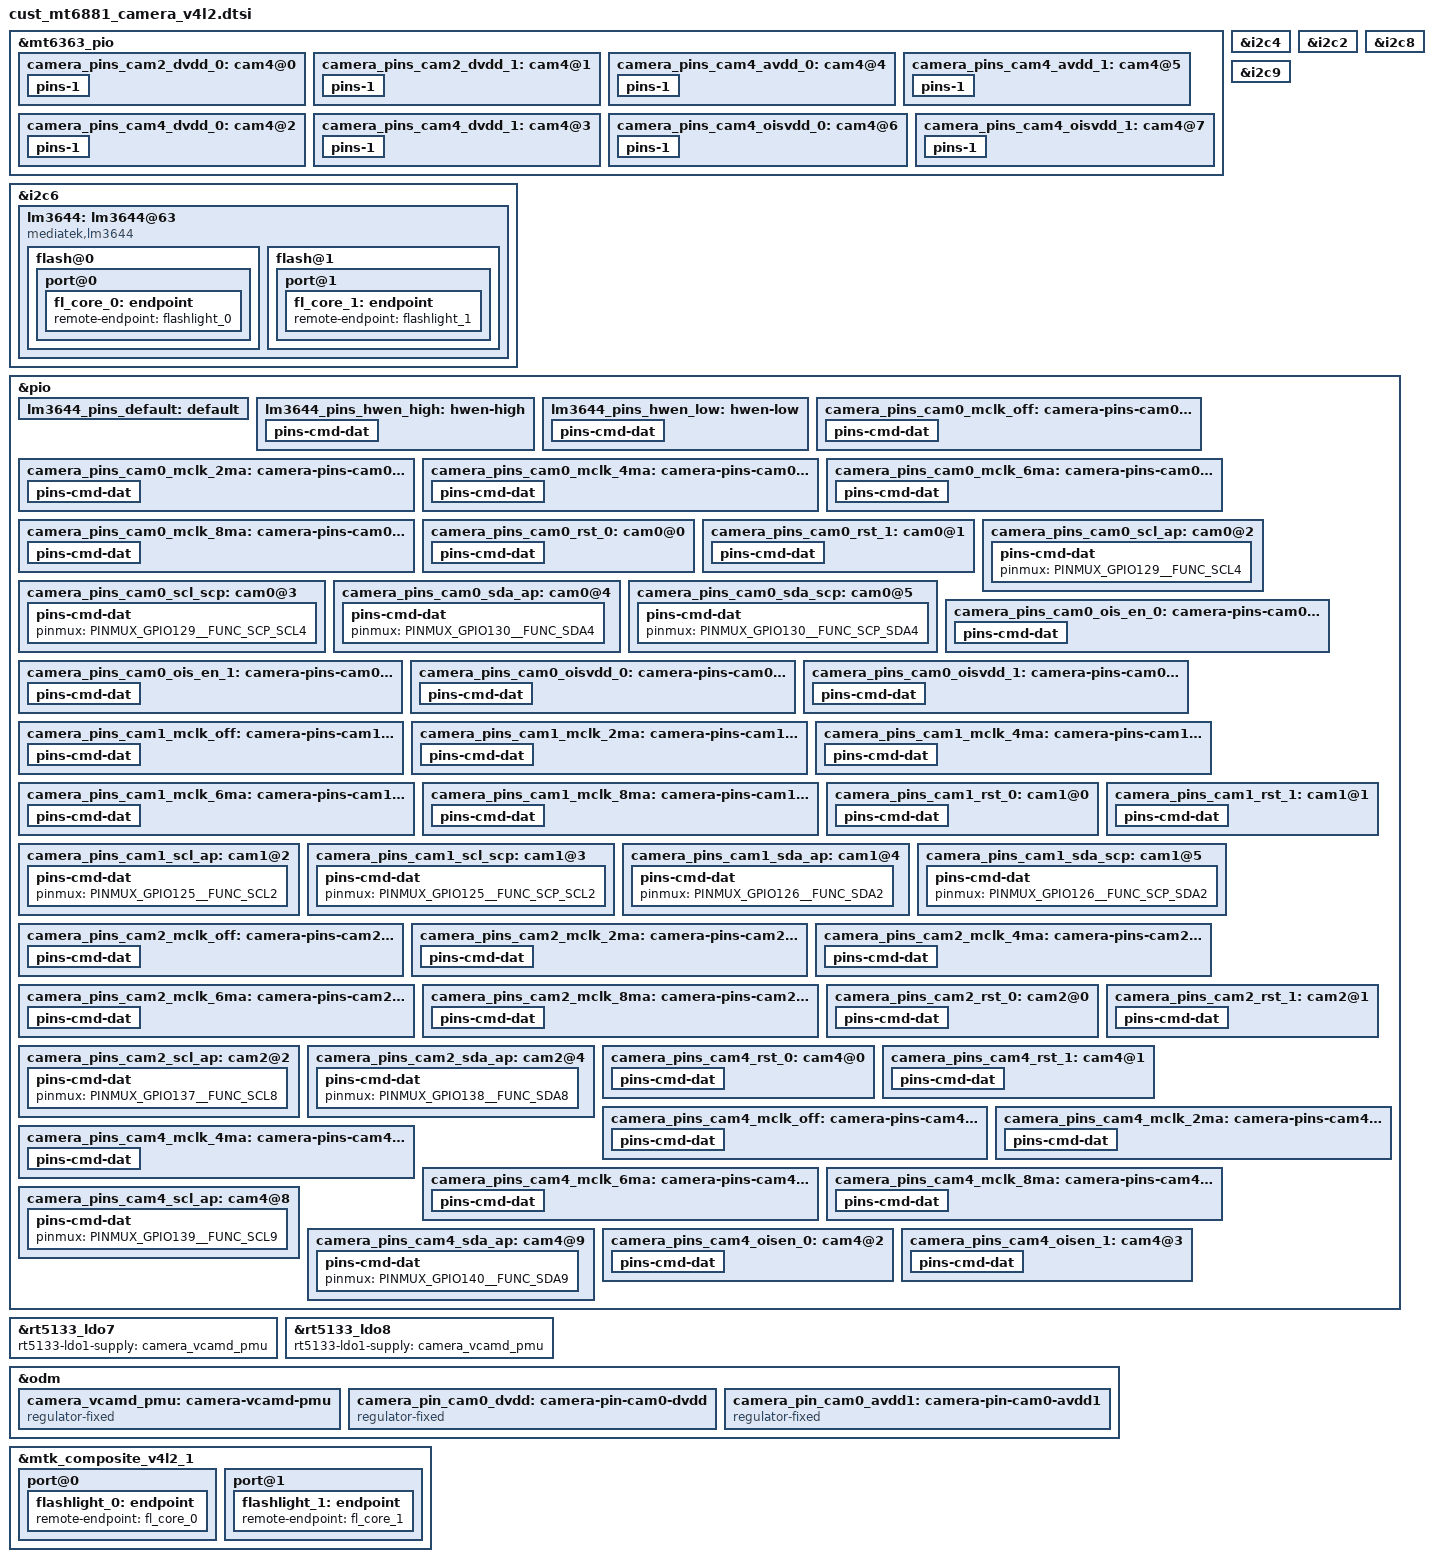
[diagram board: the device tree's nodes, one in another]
// SPDX-License-Identifier: GPL-2.0
/* Copyright (c) 2025 MediaTek Inc. */
#include <dt-bindings/clock/mt6881-clk.h>
#include <dt-bindings/pinctrl/mt6881-pinfunc.h>
#include <dt-bindings/pinctrl/mt6363-pinfunc.h>

#if 0
&seninf_top {
		seninf_csi_port_0: seninf-csi-port-0 {
			compatible = "mediatek,seninf";
			csi-port = "0";

			// nvmem-cells = <&csi_efuse0>;
			// nvmem-cell-names = "rg_csi";

			port {
				seninf_csi_port_0_in: endpoint {
					remote-endpoint = <&sensor1_out>;
				};
			};
		};

		seninf_csi_port_1: seninf-csi-port-1 {
			compatible = "mediatek,seninf";
			csi-port = "1";

			// nvmem-cells = <&csi_efuse1>;
			// nvmem-cell-names = "rg_csi";

			/* HP9 EINT */
			interrupts-extended = <&pio 23 IRQ_TYPE_EDGE_FALLING>;
			gpio-num = <23>;
			eint-no = <3>; /* Max to 3, options:{1, 2, 3} */

			port {
				seninf_csi_port_1_in: endpoint {
					remote-endpoint = <&sensor4_out>;
				};
			};
		};

		seninf_csi_port_2: seninf-csi-port-2 {
			compatible = "mediatek,seninf";
			csi-port = "2";


			// nvmem-cells = <&csi_efuse2>;
			// nvmem-cell-names = "rg_csi";


			/* JN1 EINT */
			interrupts-extended = <&pio 22 IRQ_TYPE_EDGE_FALLING>;
			gpio-num = <22>;
			eint-no = <2>; /* Max to 3, options:{1, 2, 3} */

			port {
				seninf_csi_port_2_in: endpoint {
					remote-endpoint = <&sensor2_out>;
				};
			};
		};
		seninf_csi_port_3: seninf-csi-port-3 {
			compatible = "mediatek,seninf";
			csi-port = "3";

			// nvmem-cells = <&csi_efuse3>;
			// nvmem-cell-names = "rg_csi";


			/* KOKU EINT */
			interrupts-extended = <&pio 96 IRQ_TYPE_EDGE_FALLING>;
			gpio-num = <96>;
			eint-no = <1>; /* Max to 3, options:{1, 2, 3} */

			port {
				seninf_csi_port_3_in: endpoint@1 {
					remote-endpoint = <&sensor0_out>;
				};
			};
		};
};
#endif

&mt6363_pio {
	camera_pins_cam2_dvdd_0: cam4@0 {
		pins-1 {
			pinmux = <PINMUX_MT6363_GPIO4__FUNC_GPIO4>;
			drive-strengh = <15>;
			output-low;
		};
	};

	camera_pins_cam2_dvdd_1: cam4@1 {
		pins-1 {
			pinmux = <PINMUX_MT6363_GPIO4__FUNC_GPIO4>;
			drive-strengh = <15>;
			output-high;
		};
	};

	camera_pins_cam4_avdd_0: cam4@4 {
		pins-1 {
			pinmux = <PINMUX_MT6363_GPIO7__FUNC_GPIO7>;
			drive-strengh = <15>;
			output-low;
		};
	};
	camera_pins_cam4_avdd_1: cam4@5 {
		pins-1 {
			pinmux = <PINMUX_MT6363_GPIO7__FUNC_GPIO7>;
			drive-strengh = <15>;
			output-high;
		};
	};

	camera_pins_cam4_dvdd_0: cam4@2 {
		pins-1 {
			pinmux = <PINMUX_MT6363_GPIO5__FUNC_GPIO5>;
			drive-strengh = <15>;
			output-low;
		};
	};

	camera_pins_cam4_dvdd_1: cam4@3 {
		pins-1 {
			pinmux = <PINMUX_MT6363_GPIO5__FUNC_GPIO5>;
			drive-strengh = <15>;
			output-high;
		};
	};

	camera_pins_cam4_oisvdd_0: cam4@6 {
		pins-1 {
			pinmux = <PINMUX_MT6363_GPIO6__FUNC_GPIO6>;
			drive-strengh = <15>;
			output-low;
		};
	};
	camera_pins_cam4_oisvdd_1: cam4@7 {
		pins-1 {
			pinmux = <PINMUX_MT6363_GPIO6__FUNC_GPIO6>;
			drive-strengh = <15>;
			output-high;
		};
	};
};

&i2c6 {
	lm3644:lm3644@63 {
		compatible = "mediatek,lm3644";
		reg = <0x63>;
		#cooling-cells = <2>;
		pinctrl-names = "default", "hwen-high", "hwen-low";
		pinctrl-0 = <&lm3644_pins_default>;
		pinctrl-1 = <&lm3644_pins_hwen_high>;
		pinctrl-2 = <&lm3644_pins_hwen_low>;
		status = "okay";
		flash@0{
			reg = <0>;
			type = <0>;
			ct = <0>;
			part = <0>;
			port@0 {
				fl_core_0: endpoint {
					remote-endpoint = <&flashlight_0>;
				};
			};
		};
		flash@1{
			reg = <1>;
			type = <0>;
			ct = <1>;
			part = <0>;
			port@1 {
				fl_core_1: endpoint {
					remote-endpoint = <&flashlight_1>;
				};
			};
		};
	};
};

&i2c4 {
#if 0
	status = "okay";
	clock-frequency = <1000000>;

	sensor0: sensor0@36 {
		compatible = "mediatek,imgsensor";
		sensor-names = "ov48b_mipi_raw",
					"imx06c_mipi_raw";
		reg = <0x36 0 0>;
		maximum-pmic-delay = <4000>;

		#thermal-sensor-cells = <0>;

		pinctrl-names = "mclk_off",
				"mclk_2mA",
				"mclk_4mA",
				"mclk_6mA",
				"mclk_8mA",
				"rst_low",
				"rst_high",
				"scl_ap",
				"scl_scp",
				"sda_ap",
				"sda_scp",
				"oisvdd_off",
				"oisvdd_on",
				"oisen_off",
				"oisen_on";
		pinctrl-0 = <&camera_pins_cam0_mclk_off>;
		pinctrl-1 = <&camera_pins_cam0_mclk_2ma>;
		pinctrl-2 = <&camera_pins_cam0_mclk_4ma>;
		pinctrl-3 = <&camera_pins_cam0_mclk_6ma>;
		pinctrl-4 = <&camera_pins_cam0_mclk_8ma>;
		pinctrl-5 = <&camera_pins_cam0_rst_0>;
		pinctrl-6 = <&camera_pins_cam0_rst_1>;
		pinctrl-7 = <&camera_pins_cam0_scl_ap>;
		pinctrl-8 = <&camera_pins_cam0_scl_scp>;
		pinctrl-9 = <&camera_pins_cam0_sda_ap>;
		pinctrl-10 = <&camera_pins_cam0_sda_scp>;
		pinctrl-11 = <&camera_pins_cam0_oisvdd_0>;
		pinctrl-12 = <&camera_pins_cam0_oisvdd_1>;
		pinctrl-13 = <&camera_pins_cam0_ois_en_0>;
		pinctrl-14 = <&camera_pins_cam0_ois_en_1>;

		avdd-supply =  <&rt5133_ldo5>;  // 2.8V
		avdd1-supply =  <&camera_pin_cam0_avdd1>;  // 1.8V
		dvdd-supply = <&rt5133_ldo7>;  // 1.1v for ov48b
		dvdd1-supply = <&camera_pin_cam0_dvdd>;  // 0.81v for tri cam
		afvdd1-supply = <&rt5133_gpio1>;
		dovdd-supply = <&camera_vcamd_pmu>;  // iovdd 1.8v share
		base-supply = <&rt5133_base>;

		clocks = <&cksys_reg_clk CLK_CKSYS_REG_UNIVPLL_192M_D32>,
			<&cksys_reg_clk CLK_CKSYS_REG_UNIVPLL_192M_D16>,
			<&cksys_reg_clk CLK_CKSYS_REG_F26M_CK_D2>,
			<&cksys_reg_clk CLK_CKSYS_REG_UNIVPLL_192M_D10>,
			<&cksys_reg_clk CLK_CKSYS_REG_UNIVPLL_192M_D8>,
			<&cksys_reg_clk CLK_CKSYS_REG_TCK_26M_MX9>,
			<&cksys_reg_clk CLK_CKSYS_REG_OSC_D10>,
			<&cksys_reg_clk CLK_CKSYS_REG_UNIVPLL_D6_D8>,
			<&cksys_reg_clk CLK_CKSYS_REG_CAMTG1_SEL>;

		clock-names = "6", "12", "13", "19.2", "24", "26", "26_ulposc", "52", "mclk";


		status = "okay";
		port {
			sensor0_out: endpoint {
				remote-endpoint = <&seninf_csi_port_3_in>;
			};
		};
	};

	mtk_camera_eeprom:camera-eeprom0@50 {
		compatible = "mediatek,camera_eeprom";
		reg = <0x50 0 0>;
		names = "imx06c_cust_eeprom",
			"ov48b_mtk_eeprom";
		status = "okay";
	};
#endif
};

&i2c2 {
#if 0
	status = "okay";
	clock-frequency = <1000000>;

	sensor1: sensor1@10 {
		compatible = "mediatek,imgsensor";
		sensor-names = "s5k3p9sp_mipi_raw";
		reg = <0x10>;
		maximum-pmic-delay = <4000>;

		#thermal-sensor-cells = <0>;

		pinctrl-names = "mclk_off",
				"mclk_2mA",
				"mclk_4mA",
				"mclk_6mA",
				"mclk_8mA",
				"rst_low",
				"rst_high",
				"scl_ap",
				"scl_scp",
				"sda_ap",
				"sda_scp";
		pinctrl-0 = <&camera_pins_cam1_mclk_off>;
		pinctrl-1 = <&camera_pins_cam1_mclk_2ma>;
		pinctrl-2 = <&camera_pins_cam1_mclk_4ma>;
		pinctrl-3 = <&camera_pins_cam1_mclk_6ma>;
		pinctrl-4 = <&camera_pins_cam1_mclk_8ma>;
		pinctrl-5 = <&camera_pins_cam1_rst_0>;
		pinctrl-6 = <&camera_pins_cam1_rst_1>;
		pinctrl-7 = <&camera_pins_cam1_scl_ap>;
		pinctrl-8 = <&camera_pins_cam1_scl_scp>;
		pinctrl-9 = <&camera_pins_cam1_sda_ap>;
		pinctrl-10 = <&camera_pins_cam1_sda_scp>;

		avdd-supply = <&rt5133_ldo3>;
		dvdd-supply = <&rt5133_gpio3>;
		dovdd-supply = <&camera_vcamd_pmu>;
		base-supply = <&rt5133_base>;

		clocks = <&cksys_reg_clk CLK_CKSYS_REG_UNIVPLL_192M_D32>,
			<&cksys_reg_clk CLK_CKSYS_REG_UNIVPLL_192M_D16>,
			<&cksys_reg_clk CLK_CKSYS_REG_F26M_CK_D2>,
			<&cksys_reg_clk CLK_CKSYS_REG_UNIVPLL_192M_D10>,
			<&cksys_reg_clk CLK_CKSYS_REG_UNIVPLL_192M_D8>,
			<&cksys_reg_clk CLK_CKSYS_REG_TCK_26M_MX9>,
			<&cksys_reg_clk CLK_CKSYS_REG_OSC_D10>,
			<&cksys_reg_clk CLK_CKSYS_REG_UNIVPLL_D6_D8>,
			<&cksys_reg_clk CLK_CKSYS_REG_CAMTG0_SEL>;
		clock-names = "6", "12", "13", "19.2", "24", "26", "26_ulposc", "52", "mclk";

		status = "okay";
		port {
			sensor1_out: endpoint {
				remote-endpoint = <&seninf_csi_port_0_in>;
			};
		};
	};

	mtk_camera_eeprom1:camera-eeprom1@50 {
		compatible = "mediatek,camera_eeprom";
		reg = <0x50 0 0>;
		names = "s5k3p9sp_mtk_eeprom";
		status = "okay";
	};
#endif
};

&i2c8 {
#if 0
	status = "okay";
	clock-frequency = <1000000>;

	sensor2: sensor2@10 {
		compatible = "mediatek,imgsensor";
		sensor-names = "s5kjn1_mipi_raw";
		reg = <0x10>;
		maximum-pmic-delay = <4000>;

		cust-aov-csi-clk = <312>;

		#thermal-sensor-cells = <0>;

		pinctrl-names = "mclk_off",
				"mclk_2mA",
				"mclk_4mA",
				"mclk_6mA",
				"mclk_8mA",
				"rst_low",
				"rst_high",
				"dvdd_off",
				"dvdd_on",
				"scl_ap",
				"sda_ap";

		pinctrl-0 = <&camera_pins_cam2_mclk_off>;
		pinctrl-1 = <&camera_pins_cam2_mclk_2ma>;
		pinctrl-2 = <&camera_pins_cam2_mclk_4ma>;
		pinctrl-3 = <&camera_pins_cam2_mclk_6ma>;
		pinctrl-4 = <&camera_pins_cam2_mclk_8ma>;
		pinctrl-5 = <&camera_pins_cam2_rst_0>;
		pinctrl-6 = <&camera_pins_cam2_rst_1>;
		pinctrl-7 = <&camera_pins_cam2_dvdd_0>;
		pinctrl-8 = <&camera_pins_cam2_dvdd_1>;
		pinctrl-9 = <&camera_pins_cam2_scl_ap>;
		pinctrl-10 = <&camera_pins_cam2_sda_ap>;

		avdd-supply = <&rt5133_ldo3>;
		afvdd-supply = <&rt5133_ldo2>;
		dovdd-supply = <&camera_vcamd_pmu>;
		base-supply = <&rt5133_base>;

		clocks = <&cksys_reg_clk CLK_CKSYS_REG_UNIVPLL_192M_D32>,
			<&cksys_reg_clk CLK_CKSYS_REG_UNIVPLL_192M_D16>,
			<&cksys_reg_clk CLK_CKSYS_REG_F26M_CK_D2>,
			<&cksys_reg_clk CLK_CKSYS_REG_UNIVPLL_192M_D10>,
			<&cksys_reg_clk CLK_CKSYS_REG_UNIVPLL_192M_D8>,
			<&cksys_reg_clk CLK_CKSYS_REG_TCK_26M_MX9>,
			<&cksys_reg_clk CLK_CKSYS_REG_OSC_D10>,
			<&cksys_reg_clk CLK_CKSYS_REG_UNIVPLL_D6_D8>,
			<&cksys_reg_clk CLK_CKSYS_REG_CAMTG4_SEL>;
		clock-names = "6", "12", "13", "19.2", "24", "26", "26_ulposc", "52", "mclk";

		status = "okay";
		port {
			sensor2_out: endpoint {
				remote-endpoint = <&seninf_csi_port_2_in>;
			};
		};
	};

	mtk_camera_eeprom2:camera-eeprom2@54 {
		compatible = "mediatek,camera_eeprom";
		reg = <0x54>;
		names = "s5kjn1_cust_eeprom";
		status = "okay";
	};
#endif
};

&i2c9 {
#if 0
	compatible = "mediatek,mt6991-i3c";
	#address-cells = <3>;
	#size-cells = <0>;
	i3c-scl-hz = <12000000>;
	status = "okay";

	sensor4: sensor4@10 {
		compatible = "mediatek,imgsensor";
		sensor-names = "s5khp9sp_mipi_raw";
		reg = <0x26 0x0216 0x1b730000>;
		assigned-address = <0x26>;
		pre-cfg-addr = <0x10>;
		maximum-pmic-delay = <4000>;

		#thermal-sensor-cells = <0>;

		pinctrl-names = "mclk_off",
				"mclk_2mA",
				"mclk_4mA",
				"mclk_6mA",
				"mclk_8mA",
				"rst_low",
				"rst_high",
				"scl_ap",
				"sda_ap",
				"avdd_off",
				"avdd_on",
				"dvdd_off",
				"dvdd_on",
				"oisvdd_off",
				"oisvdd_on",
				"oisen_off",
				"oisen_on";
		pinctrl-0 = <&camera_pins_cam4_mclk_off>;
		pinctrl-1 = <&camera_pins_cam4_mclk_2ma>;
		pinctrl-2 = <&camera_pins_cam4_mclk_4ma>;
		pinctrl-3 = <&camera_pins_cam4_mclk_6ma>;
		pinctrl-4 = <&camera_pins_cam4_mclk_8ma>;
		pinctrl-5 = <&camera_pins_cam4_rst_0>;
		pinctrl-6 = <&camera_pins_cam4_rst_1>;
		pinctrl-7 = <&camera_pins_cam4_scl_ap>;
		pinctrl-8 = <&camera_pins_cam4_sda_ap>;
		pinctrl-9 = <&camera_pins_cam4_avdd_0>;
		pinctrl-10 = <&camera_pins_cam4_avdd_1>;
		pinctrl-11 = <&camera_pins_cam4_dvdd_0>;
		pinctrl-12 = <&camera_pins_cam4_dvdd_1>;
		pinctrl-13 = <&camera_pins_cam4_oisvdd_0>;
		pinctrl-14 = <&camera_pins_cam4_oisvdd_1>;
		pinctrl-15 = <&camera_pins_cam4_oisen_0>;
		pinctrl-16 = <&camera_pins_cam4_oisen_1>;

		afvdd-supply = <&rt5133_ldo2>;
		dovdd-supply = <&camera_vcamd_pmu>;
		base-supply = <&rt5133_base>;

		clocks = <&cksys_reg_clk CLK_CKSYS_REG_UNIVPLL_192M_D32>,
			<&cksys_reg_clk CLK_CKSYS_REG_UNIVPLL_192M_D16>,
			<&cksys_reg_clk CLK_CKSYS_REG_F26M_CK_D2>,
			<&cksys_reg_clk CLK_CKSYS_REG_UNIVPLL_192M_D10>,
			<&cksys_reg_clk CLK_CKSYS_REG_UNIVPLL_192M_D8>,
			<&cksys_reg_clk CLK_CKSYS_REG_TCK_26M_MX9>,
			<&cksys_reg_clk CLK_CKSYS_REG_OSC_D10>,
			<&cksys_reg_clk CLK_CKSYS_REG_UNIVPLL_D6_D8>,
			<&cksys_reg_clk CLK_CKSYS_REG_CAMTG2_SEL>;

		clock-names = "6", "12", "13", "19.2", "24", "26", "26_ulposc", "52", "mclk";


		status = "okay";
		port {
			sensor4_out: endpoint {
				remote-endpoint = <&seninf_csi_port_1_in>;
			};
		};
	};

	mtk_camera_eeprom4:camera-eeprom4@55 {
		compatible = "mediatek,camera_eeprom";
		reg = <0x55 0 0>;
		names = "s5khp9sp_cust_eeprom";
		status = "okay";
	};
#endif
};

&pio {
	lm3644_pins_default: default {
	};

	lm3644_pins_hwen_high: hwen-high {
		pins-cmd-dat {
			pinmux = <PINMUX_GPIO99__FUNC_GPIO99>;
			slew-rate = <1>;
			output-high;
		};
	};

	lm3644_pins_hwen_low: hwen-low {
		pins-cmd-dat {
			pinmux = <PINMUX_GPIO99__FUNC_GPIO99>;
			slew-rate = <1>;
			output-low;
		};
	};

	camera_pins_cam0_mclk_off: camera-pins-cam0-mclk-off {
		pins-cmd-dat {
			pinmux = <PINMUX_GPIO67__FUNC_GPIO67>;
			drive-strength = <1>;
		};
	};
	camera_pins_cam0_mclk_2ma: camera-pins-cam0-mclk-2ma {
		pins-cmd-dat {
			pinmux = <PINMUX_GPIO67__FUNC_CMMCLK1>;
			drive-strength = <0>;
		};
	};
	camera_pins_cam0_mclk_4ma: camera-pins-cam0-mclk-4ma {
		pins-cmd-dat {
			pinmux = <PINMUX_GPIO67__FUNC_CMMCLK1>;
			drive-strength = <1>;
		};
	};
	camera_pins_cam0_mclk_6ma: camera-pins-cam0-mclk-6ma {
		pins-cmd-dat {
			pinmux = <PINMUX_GPIO67__FUNC_CMMCLK1>;
			drive-strength = <2>;
		};
	};
	camera_pins_cam0_mclk_8ma: camera-pins-cam0-mclk-8ma {
		pins-cmd-dat {
			pinmux = <PINMUX_GPIO67__FUNC_CMMCLK1>;
			drive-strength = <3>;
		};
	};

	camera_pins_cam0_rst_0: cam0@0 {
		pins-cmd-dat {
			pinmux = <PINMUX_GPIO63__FUNC_GPIO63>;
			slew-rate = <1>;
			output-low;
		};
	};
	camera_pins_cam0_rst_1: cam0@1 {
		pins-cmd-dat {
			pinmux = <PINMUX_GPIO63__FUNC_GPIO63>;
			slew-rate = <1>;
			output-high;
		};
	};

	camera_pins_cam0_scl_ap: cam0@2 {
		pins-cmd-dat {
			pinmux = <PINMUX_GPIO129__FUNC_SCL4>;
		};
	};
	camera_pins_cam0_scl_scp: cam0@3 {
		pins-cmd-dat {
			pinmux = <PINMUX_GPIO129__FUNC_SCP_SCL4>;
		};
	};
	camera_pins_cam0_sda_ap: cam0@4 {
		pins-cmd-dat {
			pinmux = <PINMUX_GPIO130__FUNC_SDA4>;
		};
	};
	camera_pins_cam0_sda_scp: cam0@5 {
		pins-cmd-dat {
			pinmux = <PINMUX_GPIO130__FUNC_SCP_SDA4>;
		};
	};
	camera_pins_cam0_ois_en_0: camera-pins-cam0-ois-en-0 {
		pins-cmd-dat {
			pinmux = <PINMUX_GPIO26__FUNC_GPIO26>;
			slew-rate = <1>;
			output-low;
		};
	};
	camera_pins_cam0_ois_en_1: camera-pins-cam0-ois-en-1 {
		pins-cmd-dat {
			pinmux = <PINMUX_GPIO26__FUNC_GPIO26>;
			slew-rate = <1>;
			output-high;
		};
	};
	camera_pins_cam0_oisvdd_0: camera-pins-cam0-oisvdd-0 {
		pins-cmd-dat {
			pinmux = <PINMUX_GPIO142__FUNC_GPIO142>;
			slew-rate = <1>;
			output-low;
		};
	};
	camera_pins_cam0_oisvdd_1: camera-pins-cam0-oisvdd-1 {
		pins-cmd-dat {
			pinmux = <PINMUX_GPIO142__FUNC_GPIO142>;
			slew-rate = <1>;
			output-high;
		};
	};

	camera_pins_cam1_mclk_off: camera-pins-cam1-mclk-off {
		pins-cmd-dat {
			pinmux = <PINMUX_GPIO66__FUNC_GPIO66>;
			drive-strength = <1>;
		};
	};
	camera_pins_cam1_mclk_2ma: camera-pins-cam1-mclk-2ma {
		pins-cmd-dat {
			pinmux = <PINMUX_GPIO66__FUNC_CMMCLK0>;
			drive-strength = <0>;
		};
	};
	camera_pins_cam1_mclk_4ma: camera-pins-cam1-mclk-4ma {
		pins-cmd-dat {
			pinmux = <PINMUX_GPIO66__FUNC_CMMCLK0>;
			drive-strength = <1>;
		};
	};
	camera_pins_cam1_mclk_6ma: camera-pins-cam1-mclk-6ma {
		pins-cmd-dat {
			pinmux = <PINMUX_GPIO66__FUNC_CMMCLK0>;
			drive-strength = <2>;
		};
	};
	camera_pins_cam1_mclk_8ma: camera-pins-cam1-mclk-8ma {
		pins-cmd-dat {
			pinmux = <PINMUX_GPIO66__FUNC_CMMCLK0>;
			drive-strength = <3>;
		};
	};
	camera_pins_cam1_rst_0: cam1@0 {
		pins-cmd-dat {
			pinmux = <PINMUX_GPIO62__FUNC_GPIO62>;
			slew-rate = <1>;
			output-low;
		};
	};
	camera_pins_cam1_rst_1: cam1@1 {
		pins-cmd-dat {
			pinmux = <PINMUX_GPIO62__FUNC_GPIO62>;
			slew-rate = <1>;
			output-high;
		};
	};
	camera_pins_cam1_scl_ap: cam1@2 {
		pins-cmd-dat {
			pinmux = <PINMUX_GPIO125__FUNC_SCL2>;
		};
	};
	camera_pins_cam1_scl_scp: cam1@3 {
		pins-cmd-dat {
			pinmux = <PINMUX_GPIO125__FUNC_SCP_SCL2>;
		};
	};
	camera_pins_cam1_sda_ap: cam1@4 {
		pins-cmd-dat {
			pinmux = <PINMUX_GPIO126__FUNC_SDA2>;
		};
	};
	camera_pins_cam1_sda_scp: cam1@5 {
		pins-cmd-dat {
			pinmux = <PINMUX_GPIO126__FUNC_SCP_SDA2>;
		};
	};

	camera_pins_cam2_mclk_off: camera-pins-cam2-mclk-off {
		pins-cmd-dat {
			pinmux = <PINMUX_GPIO68__FUNC_GPIO68>;
			drive-strength = <1>;
		};
	};
	camera_pins_cam2_mclk_2ma: camera-pins-cam2-mclk-2ma {
		pins-cmd-dat {
			pinmux = <PINMUX_GPIO68__FUNC_CMMCLK2>;
			drive-strength = <0>;
		};
	};
	camera_pins_cam2_mclk_4ma: camera-pins-cam2-mclk-4ma {
		pins-cmd-dat {
			pinmux = <PINMUX_GPIO68__FUNC_CMMCLK2>;
			drive-strength = <1>;
		};
	};
	camera_pins_cam2_mclk_6ma: camera-pins-cam2-mclk-6ma {
		pins-cmd-dat {
			pinmux = <PINMUX_GPIO68__FUNC_CMMCLK2>;
			drive-strength = <2>;
		};
	};
	camera_pins_cam2_mclk_8ma: camera-pins-cam2-mclk-8ma {
		pins-cmd-dat {
			pinmux = <PINMUX_GPIO68__FUNC_CMMCLK2>;
			drive-strength = <3>;
		};
	};
	camera_pins_cam2_rst_0: cam2@0 {
		pins-cmd-dat {
			pinmux = <PINMUX_GPIO64__FUNC_GPIO64>;
			slew-rate = <1>;
			output-low;
		};
	};
	camera_pins_cam2_rst_1: cam2@1 {
		pins-cmd-dat {
			pinmux = <PINMUX_GPIO64__FUNC_GPIO64>;
			slew-rate = <1>;
			output-high;
		};
	};
	camera_pins_cam2_scl_ap: cam2@2 {
		pins-cmd-dat {
			pinmux = <PINMUX_GPIO137__FUNC_SCL8>;
		};
	};

	camera_pins_cam2_sda_ap: cam2@4 {
		pins-cmd-dat {
			pinmux = <PINMUX_GPIO138__FUNC_SDA8>;
		};
	};

	camera_pins_cam4_rst_0: cam4@0 {
		pins-cmd-dat {
			pinmux = <PINMUX_GPIO65__FUNC_GPIO65>;
			slew-rate = <1>;
			output-low;
		};
	};
	camera_pins_cam4_rst_1: cam4@1 {
		pins-cmd-dat {
			pinmux = <PINMUX_GPIO65__FUNC_GPIO65>;
			slew-rate = <1>;
			output-high;
		};
	};
	camera_pins_cam4_mclk_off: camera-pins-cam4-mclk-off {
		pins-cmd-dat {
			pinmux = <PINMUX_GPIO69__FUNC_GPIO69>;
			drive-strength = <1>;
		};
	};
	camera_pins_cam4_mclk_2ma: camera-pins-cam4-mclk-2ma {
		pins-cmd-dat {
			pinmux = <PINMUX_GPIO69__FUNC_CMMCLK3>;
			drive-strength = <0>;
		};
	};
	camera_pins_cam4_mclk_4ma: camera-pins-cam4-mclk-4ma {
		pins-cmd-dat {
			pinmux = <PINMUX_GPIO69__FUNC_CMMCLK3>;
			drive-strength = <1>;
		};
	};
	camera_pins_cam4_mclk_6ma: camera-pins-cam4-mclk-6ma {
		pins-cmd-dat {
			pinmux = <PINMUX_GPIO69__FUNC_CMMCLK3>;
			drive-strength = <2>;
		};
	};
	camera_pins_cam4_mclk_8ma: camera-pins-cam4-mclk-8ma {
		pins-cmd-dat {
			pinmux = <PINMUX_GPIO69__FUNC_CMMCLK3>;
			drive-strength = <3>;
		};
	};

	camera_pins_cam4_scl_ap: cam4@8 {
		pins-cmd-dat {
			pinmux = <PINMUX_GPIO139__FUNC_SCL9>;
		};
	};
	camera_pins_cam4_sda_ap: cam4@9 {
		pins-cmd-dat {
			pinmux = <PINMUX_GPIO140__FUNC_SDA9>;
		};
	};

	camera_pins_cam4_oisen_0: cam4@2 {
		pins-cmd-dat {
			pinmux = <PINMUX_GPIO27__FUNC_GPIO27>;
			slew-rate = <1>;
			output-low;
		};
	};
	camera_pins_cam4_oisen_1: cam4@3 {
		pins-cmd-dat {
			pinmux = <PINMUX_GPIO27__FUNC_GPIO27>;
			slew-rate = <1>;
			output-high;
		};
	};
};

&rt5133_ldo7 {
	rt5133-ldo1-supply = <&camera_vcamd_pmu>;
};

&rt5133_ldo8 {
	rt5133-ldo1-supply = <&camera_vcamd_pmu>;
};

&odm {
	camera_vcamd_pmu: camera-vcamd-pmu {
		compatible = "regulator-fixed";
		regulator-name = "amera-vcamd-pmu";
		regulator-min-microvolt = <1800000>;
		regulator-max-microvolt = <1800000>;
		enable-active-high;
		gpio = <&pio 144 0x0>;
	};

	camera_pin_cam0_dvdd:camera-pin-cam0-dvdd {
		compatible = "regulator-fixed";
		regulator-name = "camera-pin-cam0-dvdd";
		regulator-min-microvolt = <1800000>;
		regulator-max-microvolt = <1800000>;
		enable-active-high;
		gpio = <&pio 32 0x0>;
	};

	camera_pin_cam0_avdd1:camera-pin-cam0-avdd1 {
		compatible = "regulator-fixed";
		regulator-name = "camera-pin-cam0-avdd1";
		regulator-min-microvolt = <1800000>;
		regulator-max-microvolt = <1800000>;
		enable-active-high;
		gpio = <&pio 33 0x0>;
	};
};

&mtk_composite_v4l2_1 {
	port@0 {
		flashlight_0: endpoint {
			remote-endpoint = <&fl_core_0>;
		};
	};
	port@1 {
		flashlight_1: endpoint {
			remote-endpoint = <&fl_core_1>;
		};
	};
};
